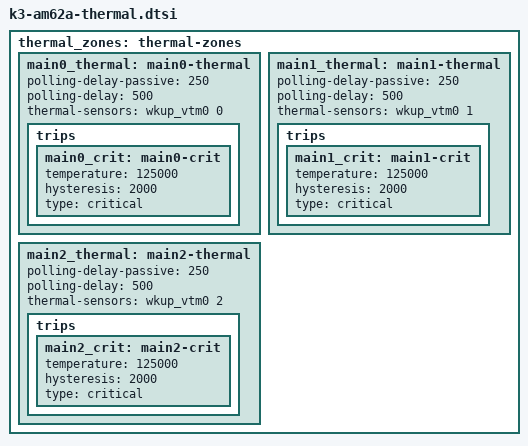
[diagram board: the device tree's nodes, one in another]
#include <dt-bindings/thermal/thermal.h>
thermal_zones: thermal-zones {
	main0_thermal: main0-thermal {
		polling-delay-passive = <250>;	 
		polling-delay = <500>;		 
		thermal-sensors = <&wkup_vtm0 0>;
		trips {
			main0_crit: main0-crit {
				temperature = <125000>;	 
				hysteresis = <2000>;	 
				type = "critical";
			};
		};
	};
	main1_thermal: main1-thermal {
		polling-delay-passive = <250>;	 
		polling-delay = <500>;		 
		thermal-sensors = <&wkup_vtm0 1>;
		trips {
			main1_crit: main1-crit {
				temperature = <125000>;	 
				hysteresis = <2000>;	 
				type = "critical";
			};
		};
	};
	main2_thermal: main2-thermal {
	       polling-delay-passive = <250>;	 
	       polling-delay = <500>;		 
	       thermal-sensors = <&wkup_vtm0 2>;
		trips {
			main2_crit: main2-crit {
				temperature = <125000>;	 
				hysteresis = <2000>;	 
				type = "critical";
			};
		};
	};
};
